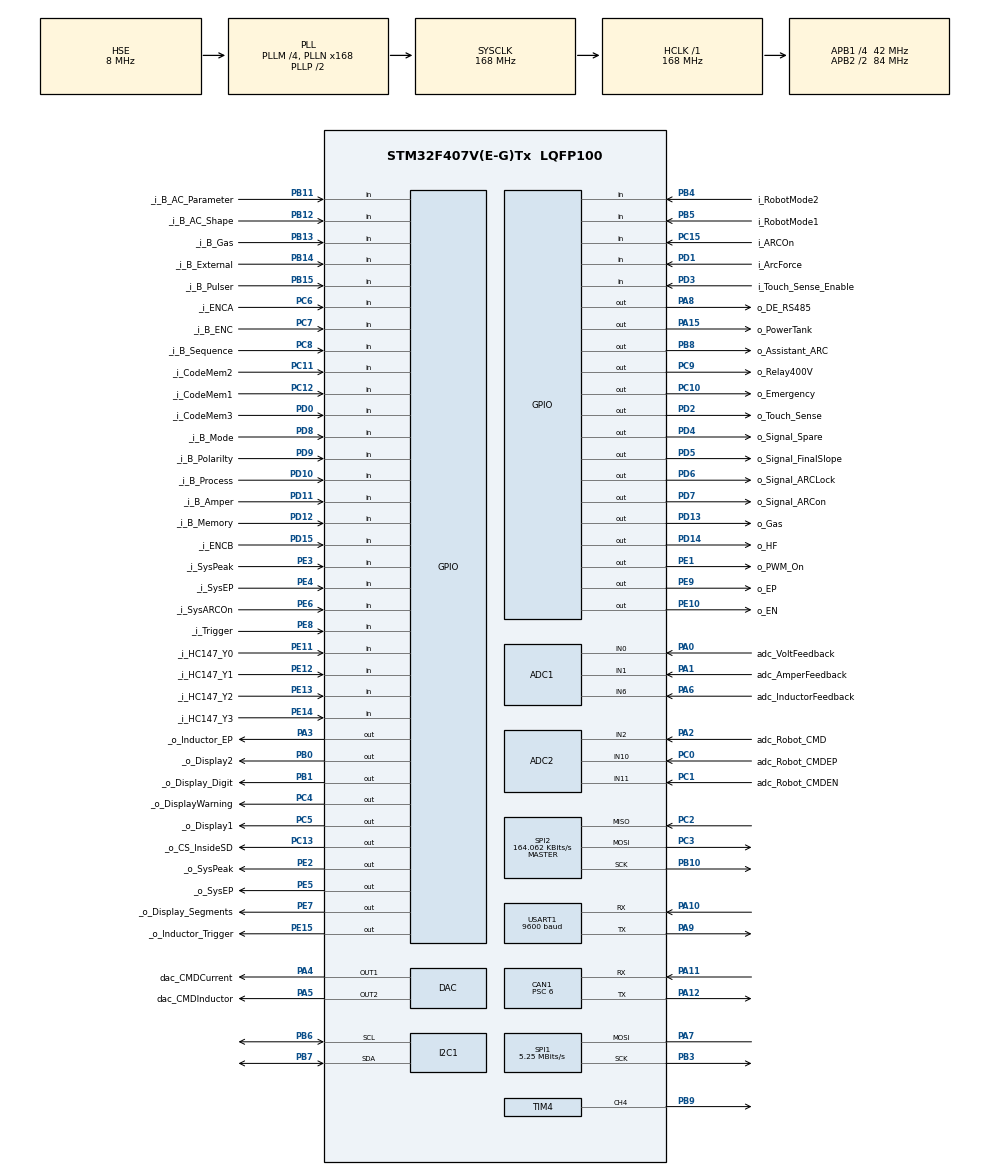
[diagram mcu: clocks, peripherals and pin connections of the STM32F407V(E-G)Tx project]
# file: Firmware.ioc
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ADC1.Channel-0\#ChannelRegularConversion=ADC_CHANNEL_0
ADC1.Channel-4\#ChannelRegularConversion=ADC_CHANNEL_1
ADC1.Channel-5\#ChannelRegularConversion=ADC_CHANNEL_6
ADC1.ClockPrescaler=ADC_CLOCK_SYNC_PCLK_DIV4
ADC1.DMAContinuousRequests=ENABLE
ADC1.EOCSelection=ADC_EOC_SEQ_CONV
ADC1.EnableAnalogWatchDog=false
ADC1.ExternalTrigConv=ADC_EXTERNALTRIGCONV_T2_TRGO
ADC1.InjNumberOfConversion=0
ADC1.NbrOfConversion=3
ADC1.NbrOfConversionFlag=1
ADC1.Rank-0\#ChannelRegularConversion=1
ADC1.Rank-4\#ChannelRegularConversion=2
ADC1.Rank-5\#ChannelRegularConversion=3
ADC1.SamplingTime-0\#ChannelRegularConversion=ADC_SAMPLETIME_15CYCLES
ADC1.SamplingTime-4\#ChannelRegularConversion=ADC_SAMPLETIME_15CYCLES
ADC1.SamplingTime-5\#ChannelRegularConversion=ADC_SAMPLETIME_15CYCLES
ADC1.master=1
ADC2.Channel-0\#ChannelRegularConversion=ADC_CHANNEL_2
ADC2.Channel-1\#ChannelRegularConversion=ADC_CHANNEL_10
ADC2.Channel-2\#ChannelRegularConversion=ADC_CHANNEL_11
ADC2.ClockPrescaler=ADC_CLOCK_SYNC_PCLK_DIV4
ADC2.DMAContinuousRequests=ENABLE
ADC2.EOCSelection=ADC_EOC_SEQ_CONV
ADC2.ExternalTrigConv=ADC_EXTERNALTRIGCONV_T2_TRGO
ADC2.NbrOfConversion=3
ADC2.NbrOfConversionFlag=1
ADC2.Rank-0\#ChannelRegularConversion=1
ADC2.Rank-1\#ChannelRegularConversion=2
ADC2.Rank-2\#ChannelRegularConversion=3
ADC2.SamplingTime-0\#ChannelRegularConversion=ADC_SAMPLETIME_15CYCLES
ADC2.SamplingTime-1\#ChannelRegularConversion=ADC_SAMPLETIME_15CYCLES
ADC2.SamplingTime-2\#ChannelRegularConversion=ADC_SAMPLETIME_15CYCLES
ADC2.ScanConvMode=ENABLE
CAN1.BS1=CAN_BS1_12TQ
CAN1.CalculateBaudRate=500000
CAN1.CalculateTimeBit=2000
CAN1.CalculateTimeQuantum=142.85714285714286
CAN1.Prescaler=6
DAC.DAC_OutputBuffer=DAC_OUTPUTBUFFER_DISABLE
DAC.DAC_OutputBuffer2=DAC_OUTPUTBUFFER_DISABLE
DAC.DAC_Trigger=DAC_TRIGGER_NONE
DAC.DAC_Trigger2=DAC_TRIGGER_NONE
Dma.ADC1.0.Direction=DMA_PERIPH_TO_MEMORY
Dma.ADC1.0.FIFOMode=DMA_FIFOMODE_DISABLE
Dma.ADC1.0.Instance=DMA2_Stream0
Dma.ADC1.0.MemDataAlignment=DMA_MDATAALIGN_HALFWORD
Dma.ADC1.0.MemInc=DMA_MINC_ENABLE
Dma.ADC1.0.Mode=DMA_CIRCULAR
Dma.ADC1.0.PeriphDataAlignment=DMA_PDATAALIGN_HALFWORD
Dma.ADC1.0.PeriphInc=DMA_PINC_DISABLE
Dma.ADC1.0.Priority=DMA_PRIORITY_VERY_HIGH
Dma.ADC2.1.Direction=DMA_PERIPH_TO_MEMORY
Dma.ADC2.1.FIFOMode=DMA_FIFOMODE_DISABLE
Dma.ADC2.1.Instance=DMA2_Stream2
Dma.ADC2.1.MemDataAlignment=DMA_MDATAALIGN_HALFWORD
Dma.ADC2.1.MemInc=DMA_MINC_ENABLE
Dma.ADC2.1.Mode=DMA_CIRCULAR
Dma.ADC2.1.PeriphDataAlignment=DMA_PDATAALIGN_HALFWORD
Dma.ADC2.1.PeriphInc=DMA_PINC_DISABLE
Dma.ADC2.1.Priority=DMA_PRIORITY_HIGH
Dma.Request0=ADC1
Dma.Request1=ADC2
Dma.Request2=USART1_RX
Dma.Request3=USART1_TX
Dma.USART1_RX.2.Direction=DMA_PERIPH_TO_MEMORY
Dma.USART1_RX.2.FIFOMode=DMA_FIFOMODE_DISABLE
Dma.USART1_RX.2.Instance=DMA2_Stream5
Dma.USART1_RX.2.MemDataAlignment=DMA_MDATAALIGN_BYTE
Dma.USART1_RX.2.MemInc=DMA_MINC_ENABLE
Dma.USART1_RX.2.Mode=DMA_NORMAL
Dma.USART1_RX.2.PeriphDataAlignment=DMA_PDATAALIGN_BYTE
Dma.USART1_RX.2.PeriphInc=DMA_PINC_DISABLE
Dma.USART1_RX.2.Priority=DMA_PRIORITY_HIGH
Dma.USART1_TX.3.Direction=DMA_MEMORY_TO_PERIPH
Dma.USART1_TX.3.FIFOMode=DMA_FIFOMODE_DISABLE
Dma.USART1_TX.3.Instance=DMA2_Stream7
Dma.USART1_TX.3.MemDataAlignment=DMA_MDATAALIGN_BYTE
Dma.USART1_TX.3.MemInc=DMA_MINC_ENABLE
Dma.USART1_TX.3.Mode=DMA_NORMAL
Dma.USART1_TX.3.PeriphDataAlignment=DMA_PDATAALIGN_BYTE
Dma.USART1_TX.3.PeriphInc=DMA_PINC_DISABLE
Dma.USART1_TX.3.Priority=DMA_PRIORITY_MEDIUM
FATFS._CODE_PAGE=437
FATFS._FS_TINY=0
FATFS._USE_EXPAND=1
FATFS._USE_FIND=0
FATFS._USE_MKFS=0
FATFS._USE_STRFUNC=2
FREERTOS.INCLUDE_pcTaskGetTaskName=1
FREERTOS.INCLUDE_uxTaskGetStackHighWaterMark2=1
FREERTOS.INCLUDE_vTaskDelete=1
FREERTOS.INCLUDE_vTaskPrioritySet=1
FREERTOS.INCLUDE_vTaskSuspend=1
FREERTOS.INCLUDE_xEventGroupSetBitFromISR=1
FREERTOS.Tasks01=defaultTask,24,128,StartDefaultTask,Default,NULL,Dynamic,NULL,NULL
FREERTOS.configCHECK_FOR_STACK_OVERFLOW=2
FREERTOS.configGENERATE_RUN_TIME_STATS=1
FREERTOS.configTOTAL_HEAP_SIZE=24000
FREERTOS.configUSE_IDLE_HOOK=1
FREERTOS.configUSE_MALLOC_FAILED_HOOK=1
FREERTOS.configUSE_NEWLIB_REENTRANT=1
I2C1.I2C_Mode=I2C_Fast
Mcu.Family=STM32F4
Mcu.Name=STM32F407V(E-G)Tx
Mcu.Package=LQFP100
NVIC.CAN1_RX0_IRQn=true\:5\:0\:false\:false\:true\:true\:true\:true\:true
NVIC.DMA2_Stream0_IRQn=true\:5\:0\:false\:false\:true\:true\:false\:true\:true
NVIC.DMA2_Stream2_IRQn=true\:5\:0\:false\:false\:true\:true\:false\:true\:true
NVIC.DMA2_Stream5_IRQn=true\:5\:0\:false\:false\:true\:true\:false\:true\:true
NVIC.DMA2_Stream7_IRQn=true\:5\:0\:false\:false\:true\:true\:false\:true\:true
NVIC.I2C1_ER_IRQn=true\:5\:0\:false\:false\:true\:true\:true\:true\:true
NVIC.I2C1_EV_IRQn=true\:5\:0\:false\:false\:true\:true\:true\:true\:true
NVIC.PriorityGroup=NVIC_PRIORITYGROUP_4
NVIC.SPI2_IRQn=true\:5\:0\:false\:false\:true\:true\:true\:true\:true
NVIC.TIM1_UP_TIM10_IRQn=true\:5\:0\:true\:false\:true\:true\:true\:true\:true
NVIC.TIM2_IRQn=true\:6\:0\:true\:false\:true\:true\:true\:true\:true
NVIC.TIM3_IRQn=true\:5\:0\:false\:false\:true\:true\:true\:true\:true
NVIC.TIM5_IRQn=true\:5\:0\:false\:false\:true\:true\:true\:true\:true
NVIC.TIM6_DAC_IRQn=true\:6\:0\:true\:false\:true\:true\:true\:true\:true
NVIC.TIM7_IRQn=true\:15\:0\:false\:false\:true\:false\:false\:true\:true
NVIC.TIM8_UP_TIM13_IRQn=true\:5\:0\:false\:false\:true\:true\:true\:true\:true
NVIC.TimeBase=TIM7_IRQn
NVIC.TimeBaseIP=TIM7
NVIC.USART1_IRQn=true\:5\:0\:false\:false\:true\:true\:true\:true\:true
PA0-WKUP.GPIO_Label=adc_VoltFeedback
PA0-WKUP.Signal=ADCx_IN0
PA1.GPIO_Label=adc_AmperFeedback
PA1.Signal=ADCx_IN1
PA10.Mode=Asynchronous
PA10.Signal=USART1_RX
PA11.Mode=CAN_Activate
PA11.Signal=CAN1_RX
PA12.Mode=CAN_Activate
PA12.Signal=CAN1_TX
PA13.Mode=Serial_Wire
PA13.Signal=SYS_JTMS-SWDIO
PA14.Mode=Serial_Wire
PA14.Signal=SYS_JTCK-SWCLK
PA15.GPIO_Label=o_PowerTank
PA15.GPIO_PuPd=GPIO_PULLDOWN
PA15.Signal=GPIO_Output
PA2.GPIO_Label=adc_Robot_CMD
PA2.Signal=ADCx_IN2
PA3.GPIO_Label=_o_Inductor_EP
PA3.GPIO_PuPd=GPIO_PULLUP
PA3.GPIO_Speed=GPIO_SPEED_FREQ_VERY_HIGH
PA3.PinState=GPIO_PIN_SET
PA3.Signal=GPIO_Output
PA4.GPIO_Label=dac_CMDCurrent
PA4.Signal=COMP_DAC1_group
PA5.GPIO_Label=dac_CMDInductor
PA5.Signal=COMP_DAC2_group
PA6.GPIO_Label=adc_InductorFeedback
PA6.Signal=ADCx_IN6
PA7.Mode=Simplex_Bidirectional_Master
PA7.Signal=SPI1_MOSI
PA8.GPIO_Label=o_DE_RS485
PA8.GPIO_Speed=GPIO_SPEED_FREQ_HIGH
PA8.Signal=GPIO_Output
PA9.Mode=Asynchronous
PA9.Signal=USART1_TX
PB0.GPIO_Label=_o_Display2
PB0.GPIO_PuPd=GPIO_PULLUP
PB0.PinState=GPIO_PIN_SET
PB0.Signal=GPIO_Output
PB1.GPIO_Label=_o_Display_Digit
PB1.GPIO_PuPd=GPIO_PULLUP
PB1.PinState=GPIO_PIN_SET
PB1.Signal=GPIO_Output
PB10.Mode=Full_Duplex_Master
PB10.Signal=SPI2_SCK
PB11.GPIO_Label=_i_B_AC_Parameter
PB11.GPIO_PuPd=GPIO_PULLUP
PB11.Signal=GPIO_Input
PB12.GPIO_Label=_i_B_AC_Shape
PB12.GPIO_PuPd=GPIO_PULLUP
PB12.Signal=GPIO_Input
PB13.GPIO_Label=_i_B_Gas
PB13.GPIO_PuPd=GPIO_PULLUP
PB13.Signal=GPIO_Input
PB14.GPIO_Label=_i_B_External
PB14.GPIO_PuPd=GPIO_PULLUP
PB14.Signal=GPIO_Input
PB15.GPIO_Label=_i_B_Pulser
PB15.GPIO_PuPd=GPIO_PULLUP
PB15.Signal=GPIO_Input
PB3.Mode=Simplex_Bidirectional_Master
PB3.Signal=SPI1_SCK
PB4.GPIO_Label=i_RobotMode2
PB4.GPIO_PuPd=GPIO_PULLDOWN
PB4.Signal=GPIO_Input
PB5.GPIO_Label=i_RobotMode1
PB5.GPIO_PuPd=GPIO_PULLDOWN
PB5.Signal=GPIO_Input
PB6.Mode=I2C
PB6.Signal=I2C1_SCL
PB7.Mode=I2C
PB7.Signal=I2C1_SDA
PB8.GPIO_Label=o_Assistant_ARC
PB8.GPIO_PuPd=GPIO_PULLDOWN
PB8.GPIO_Speed=GPIO_SPEED_FREQ_VERY_HIGH
PB8.Signal=GPIO_Output
PB9.GPIO_Speed=GPIO_SPEED_FREQ_HIGH
PB9.Signal=S_TIM4_CH4
PC0.GPIO_Label=adc_Robot_CMDEP
PC0.Signal=ADCx_IN10
PC1.GPIO_Label=adc_Robot_CMDEN
PC1.Signal=ADCx_IN11
PC10.GPIO_Label=o_Emergency
PC10.GPIO_PuPd=GPIO_PULLDOWN
PC10.Signal=GPIO_Output
PC11.GPIO_Label=_i_CodeMem2
PC11.GPIO_PuPd=GPIO_PULLUP
PC11.Signal=GPIO_Input
PC12.GPIO_Label=_i_CodeMem1
PC12.GPIO_PuPd=GPIO_PULLUP
PC12.Signal=GPIO_Input
PC13-ANTI_TAMP.GPIO_Label=_o_CS_InsideSD
PC13-ANTI_TAMP.PinState=GPIO_PIN_SET
PC13-ANTI_TAMP.Signal=GPIO_Output
PC15-OSC32_OUT.GPIO_Label=i_ARCOn
PC15-OSC32_OUT.GPIO_PuPd=GPIO_PULLDOWN
PC15-OSC32_OUT.Signal=GPIO_Input
PC2.Mode=Full_Duplex_Master
PC2.Signal=SPI2_MISO
PC3.Mode=Full_Duplex_Master
PC3.Signal=SPI2_MOSI
PC4.GPIO_Label=_o_DisplayWarning
PC4.GPIO_PuPd=GPIO_PULLUP
PC4.PinState=GPIO_PIN_SET
PC4.Signal=GPIO_Output
PC5.GPIO_Label=_o_Display1
PC5.GPIO_PuPd=GPIO_PULLUP
PC5.PinState=GPIO_PIN_SET
PC5.Signal=GPIO_Output
PC6.GPIO_Label=_i_ENCA
PC6.GPIO_PuPd=GPIO_PULLUP
PC6.Signal=GPIO_Input
PC7.GPIO_Label=_i_B_ENC
PC7.GPIO_PuPd=GPIO_PULLUP
PC7.Signal=GPIO_Input
PC8.GPIO_Label=_i_B_Sequence
PC8.GPIO_PuPd=GPIO_PULLUP
PC8.Signal=GPIO_Input
PC9.GPIO_Label=o_Relay400V
PC9.GPIO_PuPd=GPIO_PULLDOWN
PC9.Signal=GPIO_Output
PD0.GPIO_Label=_i_CodeMem3
PD0.GPIO_PuPd=GPIO_PULLUP
PD0.Signal=GPIO_Input
PD1.GPIO_Label=i_ArcForce
PD1.GPIO_PuPd=GPIO_PULLDOWN
PD1.Signal=GPIO_Input
PD10.GPIO_Label=_i_B_Process
PD10.GPIO_PuPd=GPIO_PULLUP
PD10.Signal=GPIO_Input
PD11.GPIO_Label=_i_B_Amper
PD11.GPIO_PuPd=GPIO_PULLUP
PD11.Signal=GPIO_Input
PD12.GPIO_Label=_i_B_Memory
PD12.GPIO_PuPd=GPIO_PULLUP
PD12.Signal=GPIO_Input
PD13.GPIO_Label=o_Gas
PD13.GPIO_PuPd=GPIO_PULLDOWN
PD13.GPIO_Speed=GPIO_SPEED_FREQ_VERY_HIGH
PD13.PinState=GPIO_PIN_RESET
PD13.Signal=GPIO_Output
PD14.GPIO_Label=o_HF
PD14.GPIO_PuPd=GPIO_PULLDOWN
PD14.GPIO_Speed=GPIO_SPEED_FREQ_VERY_HIGH
PD14.Signal=GPIO_Output
PD15.GPIO_Label=_i_ENCB
PD15.GPIO_PuPd=GPIO_PULLUP
PD15.Signal=GPIO_Input
PD2.GPIO_Label=o_Touch_Sense
PD2.GPIO_PuPd=GPIO_PULLDOWN
PD2.Signal=GPIO_Output
PD3.GPIO_Label=i_Touch_Sense_Enable
PD3.GPIO_PuPd=GPIO_PULLDOWN
PD3.Signal=GPIO_Input
PD4.GPIO_Label=o_Signal_Spare
PD4.GPIO_PuPd=GPIO_PULLDOWN
PD4.Signal=GPIO_Output
PD5.GPIO_Label=o_Signal_FinalSlope
PD5.GPIO_PuPd=GPIO_PULLDOWN
PD5.Signal=GPIO_Output
PD6.GPIO_Label=o_Signal_ARCLock
PD6.GPIO_PuPd=GPIO_PULLDOWN
PD6.Signal=GPIO_Output
PD7.GPIO_Label=o_Signal_ARCon
PD7.GPIO_PuPd=GPIO_PULLDOWN
PD7.Signal=GPIO_Output
PD8.GPIO_Label=_i_B_Mode
PD8.GPIO_PuPd=GPIO_PULLUP
PD8.Signal=GPIO_Input
PD9.GPIO_Label=_i_B_Polarilty
PD9.GPIO_PuPd=GPIO_PULLUP
PD9.Signal=GPIO_Input
PE1.GPIO_Label=o_PWM_On
PE1.GPIO_PuPd=GPIO_PULLDOWN
PE1.Signal=GPIO_Output
PE10.GPIO_Label=o_EN
PE10.GPIO_PuPd=GPIO_PULLDOWN
PE10.GPIO_Speed=GPIO_SPEED_FREQ_VERY_HIGH
PE10.PinState=GPIO_PIN_RESET
PE10.Signal=GPIO_Output
PE11.GPIO_Label=_i_HC147_Y0
PE11.GPIO_PuPd=GPIO_PULLUP
PE11.Signal=GPIO_Input
PE12.GPIO_Label=_i_HC147_Y1
PE12.GPIO_PuPd=GPIO_PULLUP
PE12.Signal=GPIO_Input
PE13.GPIO_Label=_i_HC147_Y2
PE13.GPIO_PuPd=GPIO_PULLUP
PE13.Signal=GPIO_Input
PE14.GPIO_Label=_i_HC147_Y3
PE14.GPIO_PuPd=GPIO_PULLUP
PE14.Signal=GPIO_Input
PE15.GPIO_Label=_o_Inductor_Trigger
PE15.GPIO_Speed=GPIO_SPEED_FREQ_VERY_HIGH
PE15.PinState=GPIO_PIN_SET
PE15.Signal=GPIO_Output
PE2.GPIO_Label=_o_SysPeak
PE2.GPIO_PuPd=GPIO_PULLUP
PE2.GPIO_Speed=GPIO_SPEED_FREQ_VERY_HIGH
PE2.PinState=GPIO_PIN_SET
PE2.Signal=GPIO_Output
PE3.GPIO_Label=_i_SysPeak
PE3.GPIO_PuPd=GPIO_PULLUP
PE3.Signal=GPIO_Input
PE4.GPIO_Label=_i_SysEP
PE4.GPIO_PuPd=GPIO_PULLUP
PE4.Signal=GPIO_Input
PE5.GPIO_Label=_o_SysEP
PE5.GPIO_PuPd=GPIO_PULLUP
PE5.GPIO_Speed=GPIO_SPEED_FREQ_VERY_HIGH
PE5.PinState=GPIO_PIN_SET
PE5.Signal=GPIO_Output
PE6.GPIO_Label=_i_SysARCOn
PE6.GPIO_PuPd=GPIO_PULLUP
PE6.Signal=GPIO_Input
PE7.GPIO_Label=_o_Display_Segments
PE7.GPIO_PuPd=GPIO_PULLUP
PE7.PinState=GPIO_PIN_SET
PE7.Signal=GPIO_Output
PE8.GPIO_Label=_i_Trigger
PE8.GPIO_PuPd=GPIO_PULLUP
PE8.Signal=GPIO_Input
PE9.GPIO_Label=o_EP
PE9.GPIO_PuPd=GPIO_PULLDOWN
PE9.GPIO_Speed=GPIO_SPEED_FREQ_VERY_HIGH
PE9.PinState=GPIO_PIN_RESET
PE9.Signal=GPIO_Output
PH0-OSC_IN.Mode=HSE-External-Oscillator
PH0-OSC_IN.Signal=RCC_OSC_IN
PH1-OSC_OUT.Mode=HSE-External-Oscillator
PH1-OSC_OUT.Signal=RCC_OSC_OUT
ProjectManager.HeapSize=0x200
ProjectManager.StackSize=0x800
ProjectManager.TargetToolchain=CMake
RCC.48MHZClocksFreq_Value=84000000
RCC.AHBFreq_Value=168000000
RCC.APB1CLKDivider=RCC_HCLK_DIV4
RCC.APB1Freq_Value=42000000
RCC.APB1TimFreq_Value=84000000
RCC.APB2CLKDivider=RCC_HCLK_DIV2
RCC.APB2Freq_Value=84000000
RCC.APB2TimFreq_Value=168000000
RCC.CortexFreq_Value=168000000
RCC.HCLKFreq_Value=168000000
RCC.HSE_VALUE=8000000
RCC.HSI_VALUE=16000000
RCC.LSE_VALUE=32768
RCC.PLLM=4
RCC.PLLN=168
RCC.PLLSourceVirtual=RCC_PLLSOURCE_HSE
RCC.SYSCLKFreq_VALUE=168000000
RCC.SYSCLKSource=RCC_SYSCLKSOURCE_PLLCLK
RCC.VCOOutputFreq_Value=336000000
SH.ADCx_IN0.0=ADC1_IN0,IN0
SH.ADCx_IN1.0=ADC1_IN1,IN1
SH.ADCx_IN10.0=ADC2_IN10,IN10
SH.ADCx_IN11.0=ADC2_IN11,IN11
SH.ADCx_IN2.0=ADC2_IN2,IN2
SH.ADCx_IN6.0=ADC1_IN6,IN6
SH.COMP_DAC1_group.0=DAC_OUT1,DAC_OUT1
SH.COMP_DAC2_group.0=DAC_OUT2,DAC_OUT2
SH.S_TIM4_CH4.0=TIM4_CH4,PWM Generation4 CH4
SPI1.BaudRatePrescaler=SPI_BAUDRATEPRESCALER_16
SPI1.CalculateBaudRate=5.25 MBits/s
SPI1.Direction=SPI_DIRECTION_1LINE
SPI1.Mode=SPI_MODE_MASTER
SPI1.VirtualType=VM_MASTER
SPI2.BaudRatePrescaler=SPI_BAUDRATEPRESCALER_256
SPI2.CLKPhase=SPI_PHASE_2EDGE
SPI2.CalculateBaudRate=164.062 KBits/s
SPI2.Direction=SPI_DIRECTION_2LINES
SPI2.Mode=SPI_MODE_MASTER
SPI2.VirtualType=VM_MASTER
TIM1.AutoReloadPreload=TIM_AUTORELOAD_PRELOAD_ENABLE
TIM1.Period=19
TIM1.Prescaler=167
TIM2.AutoReloadPreload=TIM_AUTORELOAD_PRELOAD_ENABLE
TIM2.Period=99
TIM2.Prescaler=83
TIM2.TIM_MasterOutputTrigger=TIM_TRGO_UPDATE
TIM3.AutoReloadPreload=TIM_AUTORELOAD_PRELOAD_ENABLE
TIM3.Period=999
TIM3.Prescaler=83
TIM4.AutoReloadPreload=TIM_AUTORELOAD_PRELOAD_ENABLE
TIM4.Channel-PWM\ Generation4\ CH4=TIM_CHANNEL_4
TIM4.OCFastMode_PWM-PWM\ Generation4\ CH4=TIM_OCFAST_ENABLE
TIM4.Period=99
TIM4.Prescaler=55
TIM5.AutoReloadPreload=TIM_AUTORELOAD_PRELOAD_ENABLE
TIM5.Period=999
TIM5.Prescaler=83
TIM5.TIM_MasterOutputTrigger=TIM_TRGO_RESET
TIM6.AutoReloadPreload=TIM_AUTORELOAD_PRELOAD_ENABLE
TIM6.Period=49
TIM6.Prescaler=83
TIM6.TIM_MasterOutputTrigger=TIM_TRGO_RESET
TIM8.AutoReloadPreload=TIM_AUTORELOAD_PRELOAD_ENABLE
TIM8.Period=9
TIM8.Prescaler=167
USART1.BaudRate=9600
USART1.Parity=PARITY_NONE
USART1.StopBits=STOPBITS_2
USART1.VirtualMode=VM_ASYNC
VP_FATFS_VS_Generic.Mode=User_defined
VP_FREERTOS_VS_CMSIS_V2.Mode=CMSIS_V2
VP_SYS_VS_tim7.Mode=TIM7
VP_TIM1_VS_ClockSourceINT.Mode=Internal
VP_TIM2_VS_ClockSourceINT.Mode=Internal
VP_TIM3_VS_ClockSourceINT.Mode=Internal
VP_TIM4_VS_ClockSourceINT.Mode=Internal
VP_TIM5_VS_ClockSourceINT.Mode=Internal
VP_TIM6_VS_ClockSourceINT.Mode=Enable_Timer
VP_TIM8_VS_ClockSourceINT.Mode=Internal
board=custom

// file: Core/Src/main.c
/* USER CODE BEGIN Header */
/**
  ******************************************************************************
  * @file           : main.c
  * @brief          : Main program body
  ******************************************************************************
  * @attention
  *
  * Copyright (c) 2026 STMicroelectronics.
  * All rights reserved.
  *
  * This software is licensed under terms that can be found in the LICENSE file
  * in the root directory of this software component.
  * If no LICENSE file comes with this software, it is provided AS-IS.
  *
  ******************************************************************************
  */
/* USER CODE END Header */
#include "main.h"
#include "cmsis_os.h"
#include "adc.h"
#include "can.h"
#include "dac.h"
#include "dma.h"
#include "fatfs.h"
#include "i2c.h"
#include "spi.h"
#include "tim.h"
#include "usart.h"
#include "gpio.h"

/* USER CODE BEGIN Includes */
#include "app_ATest.h"

#include "app_InputDigital.h"
#include "app_RefreshUI.h"
#include "app_HMI.h"

#include "bsp_Timer.h"
#include "bsp_OutputAnalog.h"
#include "bsp_OutputDigital.h"

#include "svc_Waveform.h"
/* USER CODE END Includes */

void SystemClock_Config(void);
void MX_FREERTOS_Init(void);

int main(void)
{

  /* MCU Configuration--------------------------------------------------------*/

  /* Reset of all peripherals, Initializes the Flash interface and the Systick. */
  HAL_Init();

  /* Configure the system clock */
  SystemClock_Config();

  /* Initialize all configured peripherals */
  MX_GPIO_Init();
  MX_DMA_Init();
  MX_ADC2_Init();
  MX_SPI2_Init();
  MX_ADC1_Init();
  MX_FATFS_Init();
  MX_DAC_Init();
  MX_USART1_UART_Init();
  MX_CAN1_Init();
  MX_I2C1_Init();
  MX_TIM4_Init();
  MX_TIM6_Init();
  MX_SPI1_Init();
  MX_TIM5_Init();
  MX_TIM2_Init();
  MX_TIM1_Init();
  MX_TIM3_Init();
  MX_TIM8_Init();
  /* USER CODE BEGIN 2 */
  bsp_Timer_InitTimer();
  bsp_OutputAnalog_InitalBuffer();
  bsp_OutputDigital_Init();

  svc_Waveform_Init();
//  svc_Waveform_setIsPulse();
  /* Init scheduler */
  osKernelInitialize();  /* Call init function for freertos objects (in cmsis_os2.c) */
  MX_FREERTOS_Init();

  app_Test_Init();

  app_InputDigital_Init();
  app_RefreshUI_Init();
  app_HMI_Init();
  /* USER CODE END 2 */

//  /* Init scheduler */
//  osKernelInitialize();  /* Call init function for freertos objects (in cmsis_os2.c) */
//  MX_FREERTOS_Init();

  /* Start scheduler */
  osKernelStart();

  /* We should never get here as control is now taken by the scheduler */

  /* Infinite loop */
  while (1)
  {

  }
}

void SystemClock_Config(void)
{
  RCC_OscInitTypeDef RCC_OscInitStruct = {0};
  RCC_ClkInitTypeDef RCC_ClkInitStruct = {0};

  /** Configure the main internal regulator output voltage
  */
  __HAL_RCC_PWR_CLK_ENABLE();
  __HAL_PWR_VOLTAGESCALING_CONFIG(PWR_REGULATOR_VOLTAGE_SCALE1);

  /** Initializes the RCC Oscillators according to the specified parameters
  * in the RCC_OscInitTypeDef structure.
  */
  RCC_OscInitStruct.OscillatorType = RCC_OSCILLATORTYPE_HSE;
  RCC_OscInitStruct.HSEState = RCC_HSE_ON;
  RCC_OscInitStruct.PLL.PLLState = RCC_PLL_ON;
  RCC_OscInitStruct.PLL.PLLSource = RCC_PLLSOURCE_HSE;
  RCC_OscInitStruct.PLL.PLLM = 4;
  RCC_OscInitStruct.PLL.PLLN = 168;
  RCC_OscInitStruct.PLL.PLLP = RCC_PLLP_DIV2;
  RCC_OscInitStruct.PLL.PLLQ = 4;
  if (HAL_RCC_OscConfig(&RCC_OscInitStruct) != HAL_OK)
  {
    Error_Handler();
  }

  /** Initializes the CPU, AHB and APB buses clocks
  */
  RCC_ClkInitStruct.ClockType = RCC_CLOCKTYPE_HCLK|RCC_CLOCKTYPE_SYSCLK
                              |RCC_CLOCKTYPE_PCLK1|RCC_CLOCKTYPE_PCLK2;
  RCC_ClkInitStruct.SYSCLKSource = RCC_SYSCLKSOURCE_PLLCLK;
  RCC_ClkInitStruct.AHBCLKDivider = RCC_SYSCLK_DIV1;
  RCC_ClkInitStruct.APB1CLKDivider = RCC_HCLK_DIV4;
  RCC_ClkInitStruct.APB2CLKDivider = RCC_HCLK_DIV2;

  if (HAL_RCC_ClockConfig(&RCC_ClkInitStruct, FLASH_LATENCY_5) != HAL_OK)
  {
    Error_Handler();
  }
}

void HAL_TIM_PeriodElapsedCallback(TIM_HandleTypeDef *htim)
{
  if (htim->Instance == TIM7)
  {
    HAL_IncTick();
  }
}

void Error_Handler(void)
{
  __disable_irq();
  while (1)
  {
  }
}

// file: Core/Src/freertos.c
/* USER CODE BEGIN Header */
/**
  ******************************************************************************
  * File Name          : freertos.c
  * Description        : Code for freertos applications
  ******************************************************************************
  * @attention
  *
  * Copyright (c) 2026 STMicroelectronics.
  * All rights reserved.
  *
  * This software is licensed under terms that can be found in the LICENSE file
  * in the root directory of this software component.
  * If no LICENSE file comes with this software, it is provided AS-IS.
  *
  ******************************************************************************
  */
/* USER CODE END Header */

#include "FreeRTOS.h"
#include "task.h"
#include "main.h"
#include "cmsis_os.h"

/* Definitions for defaultTask */
osThreadId_t defaultTaskHandle;
const osThreadAttr_t defaultTask_attributes = {
  .name = "defaultTask",
  .stack_size = 128 * 4,
  .priority = (osPriority_t) osPriorityNormal,
};

void StartDefaultTask(void *argument);

void MX_FREERTOS_Init(void); /* (MISRA C 2004 rule 8.1) */

/* Hook prototypes */
void configureTimerForRunTimeStats(void);
unsigned long getRunTimeCounterValue(void);
void vApplicationIdleHook(void);
void vApplicationStackOverflowHook(xTaskHandle xTask, signed char *pcTaskName);
void vApplicationMallocFailedHook(void);

/* USER CODE BEGIN 1 */
/* Functions needed when configGENERATE_RUN_TIME_STATS is on */
__weak void configureTimerForRunTimeStats(void)
{

}

__weak unsigned long getRunTimeCounterValue(void)
{
return 0;
}
/* USER CODE END 1 */

/* USER CODE BEGIN 2 */
void vApplicationIdleHook( void )
{
   /* vApplicationIdleHook() will only be called if configUSE_IDLE_HOOK is set
   to 1 in FreeRTOSConfig.h. It will be called on each iteration of the idle
   task. It is essential that code added to this hook function never attempts
   to block in any way (for example, call xQueueReceive() with a block time
   specified, or call vTaskDelay()). If the application makes use of the
   vTaskDelete() API function (as this demo application does) then it is also
   important that vApplicationIdleHook() is permitted to return to its calling
   function, because it is the responsibility of the idle task to clean up
   memory allocated by the kernel to any task that has since been deleted. */
}
/* USER CODE END 2 */

/* USER CODE BEGIN 4 */
void vApplicationStackOverflowHook(xTaskHandle xTask, signed char *pcTaskName)
{
   /* Run time stack overflow checking is performed if
   configCHECK_FOR_STACK_OVERFLOW is defined to 1 or 2. This hook function is
   called if a stack overflow is detected. */
}
/* USER CODE END 4 */

/* USER CODE BEGIN 5 */
void vApplicationMallocFailedHook(void)
{
   /* vApplicationMallocFailedHook() will only be called if
   configUSE_MALLOC_FAILED_HOOK is set to 1 in FreeRTOSConfig.h. It is a hook
   function that will get called if a call to pvPortMalloc() fails.
   pvPortMalloc() is called internally by the kernel whenever a task, queue,
   timer or semaphore is created. It is also called by various parts of the
   demo application. If heap_1.c or heap_2.c are used, then the size of the
   heap available to pvPortMalloc() is defined by configTOTAL_HEAP_SIZE in
   FreeRTOSConfig.h, and the xPortGetFreeHeapSize() API function can be used
   to query the size of free heap space that remains (although it does not
   provide information on how the remaining heap might be fragmented). */
}
/* USER CODE END 5 */

void MX_FREERTOS_Init(void) {

  /* Create the thread(s) */
  /* creation of defaultTask */
  defaultTaskHandle = osThreadNew(StartDefaultTask, NULL, &defaultTask_attributes);

}

void StartDefaultTask(void *argument)
{
  for(;;)
  {
    osDelay(1);
  }
}
